# USCI_A0__UART_Mode_2 register map
Vendor: Texas Instruments
Peripheral module from a debugger description file (folder msp430).
Registers are 8-bit, access not given, no defined reset value unless marked. A register's access mark holds for its fields unless they carry their own. Offsets are as the file gives them; lines under a group give offsets from that group; [hi:lo] are bit positions; {n}, {i} and the like mark numbered series; 'fields as' and 'values as' point back to an identical list; <NAME> marks a mode.

## USCI_A0_UART_Mode
0x5C0 UCA0CTLW0 16-bit — USCI A0 Control Word Register 0
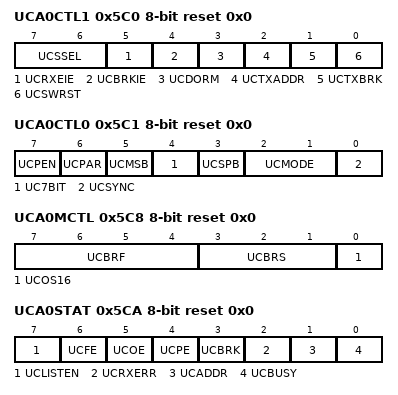
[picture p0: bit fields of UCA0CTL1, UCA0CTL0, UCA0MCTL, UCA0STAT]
0x5C0 UCA0CTL1 rw reset 0x0 — USCI A0 Control Register 1
  [7:6] UCSSEL — USCI 0 Clock Source Select 1
    {v}=USCI 0 Clock Source: {v} (v=0..3)
  [5] UCRXEIE — RX Error interrupt enable
  [4] UCBRKIE — Break interrupt enable
  [3] UCDORM — Dormant (Sleep) Mode
  [2] UCTXADDR — Send next Data as Address
  [1] UCTXBRK — Send next Data as Break
  [0] UCSWRST — USCI Software Reset
0x5C1 UCA0CTL0 rw reset 0x0 — USCI A0 Control Register 0
  [7] UCPEN — Async. Mode: Parity enable
  [6] UCPAR — Async. Mode: Parity 0:odd / 1:even
  [5] UCMSB — Async. Mode: MSB first 0:LSB / 1:MSB
  [4] UC7BIT — Async. Mode: Data Bits 0:8-bits / 1:7-bits
  [3] UCSPB — Async. Mode: Stop Bits 0:one / 1: two
  [2:1] UCMODE — Async. Mode: USCI Mode 1
    {v}=Sync. Mode: USCI Mode: {v} (v=0..3)
  [0] UCSYNC — Sync-Mode 0:UART-Mode / 1:SPI-Mode
0x5C6 UCA0BRW 16-bit — USCI A0 Baud Word Rate 0
0x5C6 UCA0BR0 — USCI A0 Baud Rate 0
0x5C7 UCA0BR1 — USCI A0 Baud Rate 1
0x5C8 UCA0MCTL rw reset 0x0 — USCI A0 Modulation Control
  [7:4] UCBRF — USCI First Stage Modulation Select 3
    {v}=USCI First Stage Modulation: {v} (v=0..9); 10=USCI First Stage Modulation: A; 11=USCI First Stage Modulation: B; 12=USCI First Stage Modulation: C; 13=USCI First Stage Modulation: D; 14=USCI First Stage Modulation: E; 15=USCI First Stage Modulation: F
  [3:1] UCBRS — USCI Second Stage Modulation Select 2
    {v}=USCI Second Stage Modulation: {v} (v=0..7)
  [0] UCOS16 — USCI 16-times Oversampling enable
0x5CA UCA0STAT rw reset 0x0 — USCI A0 Status Register
  [7] UCLISTEN — USCI Listen mode
  [6] UCFE — USCI Frame Error Flag
  [5] UCOE — USCI Overrun Error Flag
  [4] UCPE — USCI Parity Error Flag
  [3] UCBRK — USCI Break received
  [2] UCRXERR — USCI RX Error Flag
  [1] UCADDR — USCI Address received Flag
  [0] UCBUSY — USCI Busy Flag
0x5CC UCA0RXBUF — USCI A0 Receive Buffer
0x5CE UCA0TXBUF — USCI A0 Transmit Buffer
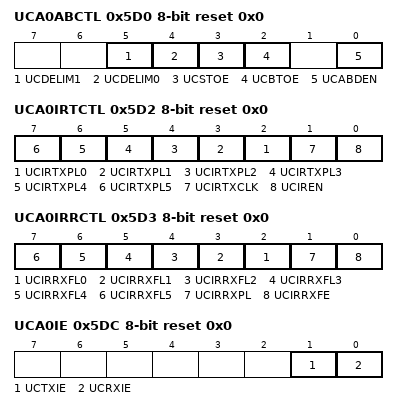
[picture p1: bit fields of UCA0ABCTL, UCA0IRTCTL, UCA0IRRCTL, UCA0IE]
0x5D0 UCA0ABCTL rw reset 0x0 — USCI A0 LIN Control
  [5] UCDELIM1 — Break Sync Delimiter 1
  [4] UCDELIM0 — Break Sync Delimiter 0
  [3] UCSTOE — Sync-Field Timeout error
  [2] UCBTOE — Break Timeout error
  [0] UCABDEN — Auto Baud Rate detect enable
0x5D2 UCA0IRCTL 16-bit — USCI A0 IrDA Transmit Control
0x5D2 UCA0IRTCTL rw reset 0x0 — USCI A0 IrDA Transmit Control
  [n+2] UCIRTXPL{n} (n=0..5) — IRDA Transmit Pulse Length {n}
  [1] UCIRTXCLK — IRDA Transmit Pulse Clock Select
  [0] UCIREN — IRDA Encoder/Decoder enable
0x5D3 UCA0IRRCTL rw reset 0x0 — USCI A0 IrDA Receive Control
  [n+2] UCIRRXFL{n} (n=0..5) — IRDA Receive Filter Length {n}
  [1] UCIRRXPL — IRDA Receive Input Polarity
  [0] UCIRRXFE — IRDA Receive Filter enable
0x5DC UCA0ICTL 16-bit — USCI A0 Interrupt Enable Register
0x5DC UCA0IE rw reset 0x0 — USCI A0 Interrupt Enable Register
  [1] UCTXIE — USCI Transmit Interrupt Enable
  [0] UCRXIE — USCI Receive Interrupt Enable
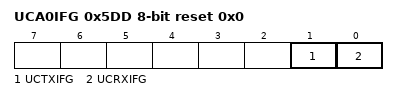
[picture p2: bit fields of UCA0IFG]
0x5DD UCA0IFG rw reset 0x0 — USCI A0 Interrupt Flags Register
  [1] UCTXIFG — USCI Transmit Interrupt Flag
  [0] UCRXIFG — USCI Receive Interrupt Flag
0x5DE UCA0IV 16-bit — USCI A0 Interrupt Vector Register
